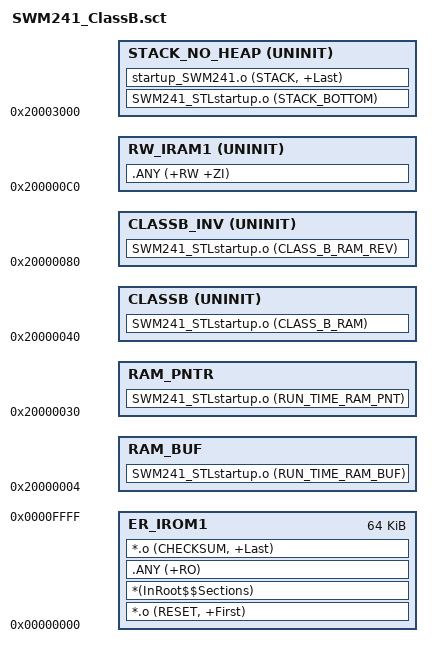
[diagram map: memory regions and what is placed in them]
; *************************************************************
; *** Scatter-Loading Description File generated by uVision ***
; *************************************************************

LR_IROM1 0x00000000 0x00010000  {    ; load region size_region
	ER_IROM1 0x00000000 0x00010000  {  ; load address = execution address
		*.o (RESET, +First)
		*(InRoot$$Sections)
		.ANY (+RO)
		*.o (CHECKSUM, +Last)
	}
	
	RAM_BUF 0x20000004 {				; Run-time transparent RAM test buffer
		SWM241_STLstartup.o (RUN_TIME_RAM_BUF)
	}

	RAM_PNTR 0x20000030	{				; Run-time transparent RAM test pointer
		SWM241_STLstartup.o (RUN_TIME_RAM_PNT)
	}

	CLASSB 0x20000040 UNINIT { 			; Class B variables
		SWM241_STLstartup.o (CLASS_B_RAM)
	}

	CLASSB_INV 0x20000080 UNINIT {		; Class B inverted variables
		SWM241_STLstartup.o (CLASS_B_RAM_REV)
	}

	RW_IRAM1 0x200000C0 UNINIT  {		; RW data (Class A variables)
		.ANY (+RW +ZI)
	}

	STACK_NO_HEAP 0x20003000 UNINIT {	; Stack and magic pattern for stack overflow detection
		SWM241_STLstartup.o (STACK_BOTTOM)
		startup_SWM241.o (STACK, +Last)
	}
}
